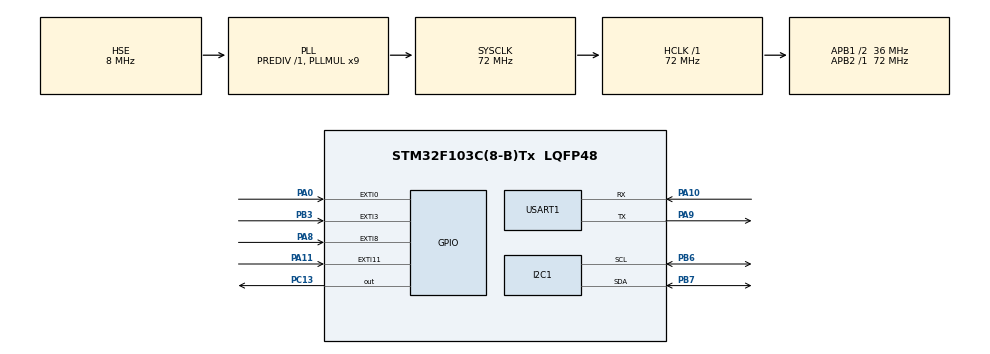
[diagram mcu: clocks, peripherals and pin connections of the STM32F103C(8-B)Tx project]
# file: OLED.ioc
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Dma.I2C1_TX.0.Direction=DMA_MEMORY_TO_PERIPH
Dma.I2C1_TX.0.Instance=DMA1_Channel6
Dma.I2C1_TX.0.MemDataAlignment=DMA_MDATAALIGN_BYTE
Dma.I2C1_TX.0.MemInc=DMA_MINC_ENABLE
Dma.I2C1_TX.0.Mode=DMA_NORMAL
Dma.I2C1_TX.0.PeriphDataAlignment=DMA_PDATAALIGN_BYTE
Dma.I2C1_TX.0.PeriphInc=DMA_PINC_DISABLE
Dma.I2C1_TX.0.Priority=DMA_PRIORITY_LOW
Dma.Request0=I2C1_TX
I2C1.I2C_Mode=I2C_Fast
Mcu.Family=STM32F1
Mcu.Name=STM32F103C(8-B)Tx
Mcu.Package=LQFP48
NVIC.DMA1_Channel6_IRQn=true\:7\:0\:true\:false\:true\:false\:true\:true
NVIC.EXTI0_IRQn=true\:15\:0\:true\:false\:true\:true\:true\:true
NVIC.EXTI15_10_IRQn=true\:5\:0\:true\:false\:true\:true\:true\:true
NVIC.EXTI3_IRQn=true\:5\:0\:true\:false\:true\:true\:true\:true
NVIC.EXTI9_5_IRQn=true\:5\:0\:true\:false\:true\:true\:true\:true
NVIC.I2C1_ER_IRQn=true\:7\:0\:true\:false\:true\:true\:true\:true
NVIC.I2C1_EV_IRQn=true\:7\:0\:true\:false\:true\:true\:true\:true
NVIC.PriorityGroup=NVIC_PRIORITYGROUP_4
NVIC.TIM2_IRQn=true\:6\:0\:true\:false\:true\:true\:true\:true
NVIC.TIM4_IRQn=true\:15\:0\:true\:false\:true\:false\:true\:true
NVIC.TimeBase=TIM4_IRQn
NVIC.TimeBaseIP=TIM4
PA0-WKUP.GPIO_PuPd=GPIO_PULLDOWN
PA0-WKUP.Signal=GPXTI0
PA10.Mode=Asynchronous
PA10.Signal=USART1_RX
PA11.GPIO_ModeDefaultEXTI=GPIO_MODE_IT_FALLING
PA11.GPIO_PuPd=GPIO_PULLUP
PA11.Signal=GPXTI11
PA13.Mode=Serial_Wire
PA13.Signal=SYS_JTMS-SWDIO
PA14.Mode=Serial_Wire
PA14.Signal=SYS_JTCK-SWCLK
PA8.GPIO_ModeDefaultEXTI=GPIO_MODE_IT_FALLING
PA8.GPIO_PuPd=GPIO_PULLUP
PA8.Signal=GPXTI8
PA9.Mode=Asynchronous
PA9.Signal=USART1_TX
PB3.GPIO_ModeDefaultEXTI=GPIO_MODE_IT_FALLING
PB3.GPIO_PuPd=GPIO_PULLUP
PB3.Signal=GPXTI3
PB6.Mode=I2C
PB6.Signal=I2C1_SCL
PB7.Mode=I2C
PB7.Signal=I2C1_SDA
PC13-TAMPER-RTC.GPIO_ModeDefaultOutputPP=GPIO_MODE_OUTPUT_PP
PC13-TAMPER-RTC.GPIO_PuPd=GPIO_PULLUP
PC13-TAMPER-RTC.PinState=GPIO_PIN_SET
PC13-TAMPER-RTC.Signal=GPIO_Output
PC14-OSC32_IN.Mode=LSE-External-Oscillator
PC14-OSC32_IN.Signal=RCC_OSC32_IN
PC15-OSC32_OUT.Mode=LSE-External-Oscillator
PC15-OSC32_OUT.Signal=RCC_OSC32_OUT
PD0-OSC_IN.Mode=HSE-External-Oscillator
PD0-OSC_IN.Signal=RCC_OSC_IN
PD1-OSC_OUT.Mode=HSE-External-Oscillator
PD1-OSC_OUT.Signal=RCC_OSC_OUT
ProjectManager.HeapSize=0x200
ProjectManager.StackSize=0x400
ProjectManager.TargetToolchain=MDK-ARM V5.32
RCC.AHBFreq_Value=72000000
RCC.APB1CLKDivider=RCC_HCLK_DIV2
RCC.APB1Freq_Value=36000000
RCC.APB1TimFreq_Value=72000000
RCC.APB2Freq_Value=72000000
RCC.APB2TimFreq_Value=72000000
RCC.HCLKFreq_Value=72000000
RCC.PLLMUL=RCC_PLL_MUL9
RCC.PLLSourceVirtual=RCC_PLLSOURCE_HSE
RCC.RTCClockSelection=RCC_RTCCLKSOURCE_LSE
RCC.SYSCLKFreq_VALUE=72000000
RCC.SYSCLKSource=RCC_SYSCLKSOURCE_PLLCLK
RCC.USBFreq_Value=72000000
RTC.Date=20
RTC.Hours=20
RTC.Minutes=15
RTC.Month=RTC_MONTH_MARCH
RTC.OutPut=RTC_OUTPUTSOURCE_NONE
RTC.WeekDay=RTC_WEEKDAY_FRIDAY
RTC.Year=26
TIM2.Period=1000
TIM2.Prescaler=72-1
USART1.VirtualMode=VM_ASYNC
VP_RTC_No_RTC_Output.Mode=RTC_OUT_NO
VP_RTC_VS_RTC_Activate.Mode=RTC_Enabled
VP_RTC_VS_RTC_Calendar.Mode=RTC_Calendar
VP_SYS_VS_tim4.Mode=TIM4
VP_TIM2_VS_ClockSourceINT.Mode=Internal
board=custom

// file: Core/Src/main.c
/* USER CODE BEGIN Header */
/**
  ******************************************************************************
  * @file           : main.c
  * @brief          : Main program body
  ******************************************************************************
  * @attention
  *
  * Copyright (c) 2025 STMicroelectronics.
  * All rights reserved.
  *
  * This software is licensed under terms that can be found in the LICENSE file
  * in the root directory of this software component.
  * If no LICENSE file comes with this software, it is provided AS-IS.
  *
  ******************************************************************************
  */
/* USER CODE END Header */
#include "main.h"
#include "dma.h"
#include "i2c.h"
#include "rtc.h"
#include "tim.h"
#include "usart.h"
#include "gpio.h"

/* USER CODE BEGIN PD */
// int fputc(int ch,FILE*f)
// {
//   HAL_UART_Transmit(&huart2,(uint8_t*)&ch,1,HAL_MAX_DELAY);
//   return ch;
// }

/* USER CODE END PD */

void SystemClock_Config(void);

/* USER CODE BEGIN 0 */

uint8_t CurrMode=1,NextMode=1;

/* USER CODE END 0 */

int main(void)
{

  /* MCU Configuration--------------------------------------------------------*/

  /* Reset of all peripherals, Initializes the Flash interface and the Systick. */
  HAL_Init();

  /* Configure the system clock */
  SystemClock_Config();

  /* USER CODE BEGIN SysInit */
    /* 检查是否是待机唤醒 */

  /* USER CODE END SysInit */

  /* Initialize all configured peripherals */
  MX_GPIO_Init();
  MX_DMA_Init();
  MX_RTC_Init();
  MX_I2C1_Init();
  MX_TIM2_Init();
  MX_USART1_UART_Init();
  /* USER CODE BEGIN 2 */
	OLED_Init();

  //HAL_TIM_Base_Stop_IT(&htim2);
  /* USER CODE END 2 */

  /* Infinite loop */
  /* USER CODE BEGIN WHILE */
 //WI_FI_Init();

  FreeRTOS_Start();

  //使PC13引脚不被RTC控制
  while (1)
  {

  }
    /* USER CODE END WHILE */

}

void SystemClock_Config(void)
{
  RCC_OscInitTypeDef RCC_OscInitStruct = {0};
  RCC_ClkInitTypeDef RCC_ClkInitStruct = {0};
  RCC_PeriphCLKInitTypeDef PeriphClkInit = {0};

  /** Initializes the RCC Oscillators according to the specified parameters
  * in the RCC_OscInitTypeDef structure.
  */
  RCC_OscInitStruct.OscillatorType = RCC_OSCILLATORTYPE_HSE|RCC_OSCILLATORTYPE_LSE;
  RCC_OscInitStruct.HSEState = RCC_HSE_ON;
  RCC_OscInitStruct.HSEPredivValue = RCC_HSE_PREDIV_DIV1;
  RCC_OscInitStruct.LSEState = RCC_LSE_ON;
  RCC_OscInitStruct.HSIState = RCC_HSI_ON;
  RCC_OscInitStruct.PLL.PLLState = RCC_PLL_ON;
  RCC_OscInitStruct.PLL.PLLSource = RCC_PLLSOURCE_HSE;
  RCC_OscInitStruct.PLL.PLLMUL = RCC_PLL_MUL9;
  if (HAL_RCC_OscConfig(&RCC_OscInitStruct) != HAL_OK)
  {
    Error_Handler();
  }

  /** Initializes the CPU, AHB and APB buses clocks
  */
  RCC_ClkInitStruct.ClockType = RCC_CLOCKTYPE_HCLK|RCC_CLOCKTYPE_SYSCLK
                              |RCC_CLOCKTYPE_PCLK1|RCC_CLOCKTYPE_PCLK2;
  RCC_ClkInitStruct.SYSCLKSource = RCC_SYSCLKSOURCE_PLLCLK;
  RCC_ClkInitStruct.AHBCLKDivider = RCC_SYSCLK_DIV1;
  RCC_ClkInitStruct.APB1CLKDivider = RCC_HCLK_DIV2;
  RCC_ClkInitStruct.APB2CLKDivider = RCC_HCLK_DIV1;

  if (HAL_RCC_ClockConfig(&RCC_ClkInitStruct, FLASH_LATENCY_2) != HAL_OK)
  {
    Error_Handler();
  }
  PeriphClkInit.PeriphClockSelection = RCC_PERIPHCLK_RTC;
  PeriphClkInit.RTCClockSelection = RCC_RTCCLKSOURCE_LSE;
  if (HAL_RCCEx_PeriphCLKConfig(&PeriphClkInit) != HAL_OK)
  {
    Error_Handler();
  }
}

void Error_Handler(void)
{
  __disable_irq();
  while (1)
  {
  }
}
